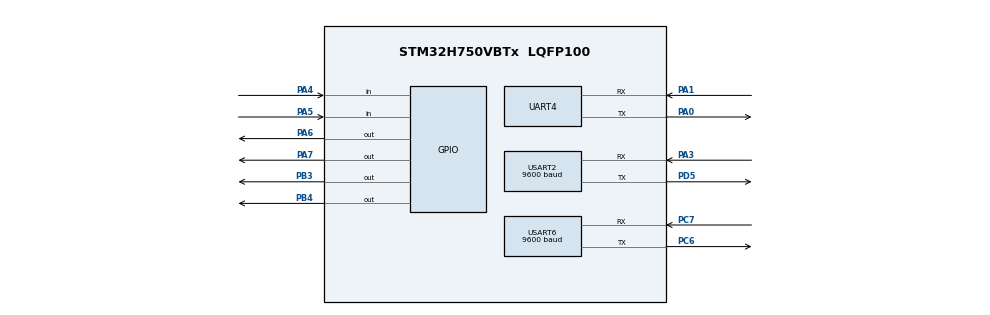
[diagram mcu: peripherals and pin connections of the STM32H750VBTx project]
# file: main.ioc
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Dma.Request0=UART4_TX
Dma.UART4_TX.0.Direction=DMA_MEMORY_TO_PERIPH
Dma.UART4_TX.0.EventEnable=DISABLE
Dma.UART4_TX.0.FIFOMode=DMA_FIFOMODE_DISABLE
Dma.UART4_TX.0.Instance=DMA1_Stream0
Dma.UART4_TX.0.MemDataAlignment=DMA_MDATAALIGN_BYTE
Dma.UART4_TX.0.MemInc=DMA_MINC_ENABLE
Dma.UART4_TX.0.Mode=DMA_NORMAL
Dma.UART4_TX.0.PeriphDataAlignment=DMA_PDATAALIGN_BYTE
Dma.UART4_TX.0.PeriphInc=DMA_PINC_DISABLE
Dma.UART4_TX.0.Polarity=HAL_DMAMUX_REQ_GEN_RISING
Dma.UART4_TX.0.Priority=DMA_PRIORITY_MEDIUM
Dma.UART4_TX.0.RequestNumber=1
Dma.UART4_TX.0.SignalID=NONE
Dma.UART4_TX.0.SyncEnable=DISABLE
Dma.UART4_TX.0.SyncPolarity=HAL_DMAMUX_SYNC_NO_EVENT
Dma.UART4_TX.0.SyncRequestNumber=1
Dma.UART4_TX.0.SyncSignalID=NONE
Mcu.Family=STM32H7
Mcu.Name=STM32H750VBTx
Mcu.Package=LQFP100
NVIC.DMA1_Stream0_IRQn=true\:0\:0\:false\:false\:true\:false\:true\:true
NVIC.PriorityGroup=NVIC_PRIORITYGROUP_4
NVIC.TIM3_IRQn=true\:5\:0\:true\:false\:true\:true\:true\:true
NVIC.TIM7_IRQn=true\:10\:0\:true\:false\:true\:true\:true\:true
NVIC.UART4_IRQn=true\:6\:0\:true\:false\:true\:true\:true\:true
NVIC.USART2_IRQn=true\:3\:0\:true\:false\:true\:true\:true\:true
NVIC.USART6_IRQn=true\:0\:0\:false\:false\:true\:true\:true\:true
PA0.Mode=Asynchronous
PA0.Signal=UART4_TX
PA1.Mode=Asynchronous
PA1.Signal=UART4_RX
PA13\ (JTMS/SWDIO).Mode=Serial_Wire
PA13\ (JTMS/SWDIO).Signal=DEBUG_JTMS-SWDIO
PA14\ (JTCK/SWCLK).Mode=Serial_Wire
PA14\ (JTCK/SWCLK).Signal=DEBUG_JTCK-SWCLK
PA3.Mode=Asynchronous
PA3.Signal=USART2_RX
PA4.Signal=GPIO_Input
PA5.Signal=GPIO_Input
PA6.Signal=GPIO_Output
PA7.Signal=GPIO_Output
PB3\ (JTDO/TRACESWO).Signal=GPIO_Output
PB4\ (NJTRST).Signal=GPIO_Output
PC14-OSC32_IN\ (OSC32_IN).Mode=LSE-External-Oscillator
PC14-OSC32_IN\ (OSC32_IN).Signal=RCC_OSC32_IN
PC15-OSC32_OUT\ (OSC32_OUT).Mode=LSE-External-Oscillator
PC15-OSC32_OUT\ (OSC32_OUT).Signal=RCC_OSC32_OUT
PC6.Mode=Asynchronous
PC6.Signal=USART6_TX
PC7.Mode=Asynchronous
PC7.Signal=USART6_RX
PD5.Mode=Asynchronous
PD5.Signal=USART2_TX
PH0-OSC_IN\ (PH0).Mode=HSE-External-Oscillator
PH0-OSC_IN\ (PH0).Signal=RCC_OSC_IN
PH1-OSC_OUT\ (PH1).Mode=HSE-External-Oscillator
PH1-OSC_OUT\ (PH1).Signal=RCC_OSC_OUT
ProjectManager.HeapSize=0x200
ProjectManager.StackSize=0x400
ProjectManager.TargetToolchain=MDK-ARM V5.32
RCC.ADCFreq_Value=16125000
RCC.APB1Freq_Value=120000000
RCC.APB2Freq_Value=120000000
RCC.APB3Freq_Value=120000000
RCC.APB4Freq_Value=120000000
RCC.CortexFreq_Value=480000000
RCC.D1PPRE=RCC_APB3_DIV2
RCC.D2PPRE1=RCC_APB1_DIV2
RCC.D2PPRE2=RCC_APB2_DIV2
RCC.D3PPRE=RCC_APB4_DIV2
RCC.DIVM1=1
RCC.DIVN1=120
RCC.HCLKFreq_Value=240000000
RCC.HPRE=RCC_HCLK_DIV2
RCC.HSE_VALUE=8000000
RCC.PLLFRACN=0
RCC.PLLSourceVirtual=RCC_PLLSOURCE_HSE
RCC.SYSCLKFreq_VALUE=480000000
RCC.SYSCLKSource=RCC_SYSCLKSOURCE_PLLCLK
RCC.USBFreq_Value=480000000
TIM3.AutoReloadPreload=TIM_AUTORELOAD_PRELOAD_ENABLE
TIM3.Period=79
TIM3.Prescaler=12000
TIM7.AutoReloadPreload=TIM_AUTORELOAD_PRELOAD_ENABLE
TIM7.Period=1000-1
TIM7.Prescaler=23999
USART2.BaudRate=9600
USART2.VirtualMode-Asynchronous=VM_ASYNC
USART6.BaudRate=9600
USART6.VirtualMode=VM_ASYNC
VP_TIM3_VS_ClockSourceINT.Mode=Internal
VP_TIM7_VS_ClockSourceINT.Mode=Enable_Timer
board=custom

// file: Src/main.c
/* USER CODE BEGIN Header */
/**
  ******************************************************************************
  * @file           : main.c
  * @brief          : Main program code
  * @note           : Modbus RTU Master test case
  ******************************************************************************
  * @attention
  *
  * Copyright (c) 2025 STMicroelectronics.
  * All rights reserved.
  *
  * This software is licensed under terms that can be found in the LICENSE file
  * in the root directory of this software component.
  * If no LICENSE file comes with this software, it is provided AS-IS.
  *
  ******************************************************************************
  */
/* USER CODE END Header */
#include "main.h"
#include "dma.h"
#include "tim.h"
#include "usart.h"
#include "gpio.h"

/* USER CODE BEGIN Includes */
#include "mb_test.h"
#include "app_manager.h"
/* USER CODE END Includes */

void SystemClock_Config(void);

int main(void)
{

  /* MCU Configuration--------------------------------------------------------*/

  /* Reset of all peripherals, Initializes the Flash interface and the Systick. */
  HAL_Init();

  /* Configure the system clock */
  SystemClock_Config();

  /* Initialize all configured peripherals */
  MX_GPIO_Init();
  MX_DMA_Init();
  MX_USART2_UART_Init();
  MX_USART6_UART_Init();
  MX_TIM3_Init();
  MX_UART4_Init();
  MX_TIM7_Init();
  /* USER CODE BEGIN 2 */

  App_Init();

  /* USER CODE END 2 */

  /* Infinite loop */
  /* USER CODE BEGIN WHILE */
  while (1)
  {
    App_Task();
    /* USER CODE END WHILE */

  }
}

void SystemClock_Config(void)
{
  RCC_OscInitTypeDef RCC_OscInitStruct = {0};
  RCC_ClkInitTypeDef RCC_ClkInitStruct = {0};

  /** Supply configuration update enable
  */
  HAL_PWREx_ConfigSupply(PWR_LDO_SUPPLY);

  /** Configure the main internal regulator output voltage
  */
  __HAL_PWR_VOLTAGESCALING_CONFIG(PWR_REGULATOR_VOLTAGE_SCALE1);

  while(!__HAL_PWR_GET_FLAG(PWR_FLAG_VOSRDY)) {}

  __HAL_RCC_SYSCFG_CLK_ENABLE();
  __HAL_PWR_VOLTAGESCALING_CONFIG(PWR_REGULATOR_VOLTAGE_SCALE0);

  while(!__HAL_PWR_GET_FLAG(PWR_FLAG_VOSRDY)) {}

  /** Initializes the RCC Oscillators according to the specified parameters
  * in the RCC_OscInitTypeDef structure.
  */
  RCC_OscInitStruct.OscillatorType = RCC_OSCILLATORTYPE_HSE;
  RCC_OscInitStruct.HSEState = RCC_HSE_ON;
  RCC_OscInitStruct.PLL.PLLState = RCC_PLL_ON;
  RCC_OscInitStruct.PLL.PLLSource = RCC_PLLSOURCE_HSE;
  RCC_OscInitStruct.PLL.PLLM = 1;
  RCC_OscInitStruct.PLL.PLLN = 120;
  RCC_OscInitStruct.PLL.PLLP = 2;
  RCC_OscInitStruct.PLL.PLLQ = 2;
  RCC_OscInitStruct.PLL.PLLR = 2;
  RCC_OscInitStruct.PLL.PLLRGE = RCC_PLL1VCIRANGE_3;
  RCC_OscInitStruct.PLL.PLLVCOSEL = RCC_PLL1VCOWIDE;
  RCC_OscInitStruct.PLL.PLLFRACN = 0;
  if (HAL_RCC_OscConfig(&RCC_OscInitStruct) != HAL_OK)
  {
    Error_Handler();
  }

  /** Initializes the CPU, AHB and APB buses clocks
  */
  RCC_ClkInitStruct.ClockType = RCC_CLOCKTYPE_HCLK|RCC_CLOCKTYPE_SYSCLK
                              |RCC_CLOCKTYPE_PCLK1|RCC_CLOCKTYPE_PCLK2
                              |RCC_CLOCKTYPE_D3PCLK1|RCC_CLOCKTYPE_D1PCLK1;
  RCC_ClkInitStruct.SYSCLKSource = RCC_SYSCLKSOURCE_PLLCLK;
  RCC_ClkInitStruct.SYSCLKDivider = RCC_SYSCLK_DIV1;
  RCC_ClkInitStruct.AHBCLKDivider = RCC_HCLK_DIV2;
  RCC_ClkInitStruct.APB3CLKDivider = RCC_APB3_DIV2;
  RCC_ClkInitStruct.APB1CLKDivider = RCC_APB1_DIV2;
  RCC_ClkInitStruct.APB2CLKDivider = RCC_APB2_DIV2;
  RCC_ClkInitStruct.APB4CLKDivider = RCC_APB4_DIV2;

  if (HAL_RCC_ClockConfig(&RCC_ClkInitStruct, FLASH_LATENCY_4) != HAL_OK)
  {
    Error_Handler();
  }
}

void Error_Handler(void)
{
  /* USER CODE BEGIN Error_Handler_Debug */
    /* User can add his own implementation to report the HAL error return state */
    __disable_irq();
    while (1)
    {
      printf("Enter Error_Handler \r\n");
      HAL_Delay(1000);
    }
  /* USER CODE END Error_Handler_Debug */
}
